# ESP32 register map
Vendor: ESPRESSIF SYSTEMS (SHANGHAI) CO., LTD.; Series: ESP32 Series; File version: 17
CPU: Xtensa LX6 r0p0, little endian, no MPU, FPU, 0 interrupt priority bits
Address unit: 32 bits
Registers are 32-bit, read-write, reset 0x0 unless marked. A register's access mark holds for its fields unless they carry their own. Offsets are from the block's base; [hi:lo] are bit positions; {n}, {i} and the like mark numbered series.

## DPORT — DPORT Peripheral
Base 0x3FF00000
0x00 PRO_BOOT_REMAP_CTRL
  [0] PRO_BOOT_REMAP
0x04 APP_BOOT_REMAP_CTRL
  [0] APP_BOOT_REMAP
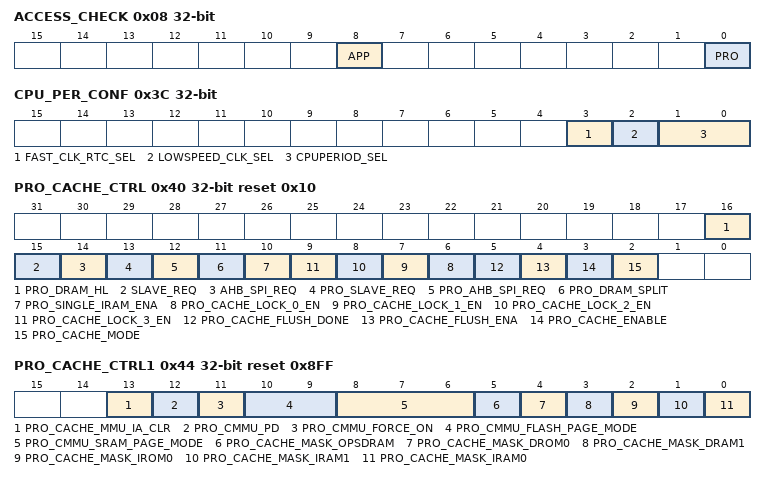
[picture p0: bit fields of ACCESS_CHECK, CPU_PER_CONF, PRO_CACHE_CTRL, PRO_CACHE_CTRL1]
0x08 ACCESS_CHECK ro
  [8] APP, [0] PRO
0x0C PRO_DPORT_APB_MASK0
  [31:0] PRODPORT_APB_MASK0
0x10 PRO_DPORT_APB_MASK1
  [31:0] PRODPORT_APB_MASK1
0x14 APP_DPORT_APB_MASK0
  [31:0] APPDPORT_APB_MASK0
0x18 APP_DPORT_APB_MASK1
  [31:0] APPDPORT_APB_MASK1
0x1C PERI_CLK_EN
0x20 PERI_RST_EN
0x24 WIFI_BB_CFG
0x28 WIFI_BB_CFG_2
0x2C APPCPU_CTRL_A reset 0x1
  [0] APPCPU_RESETTING
0x30 APPCPU_CTRL_B
  [0] APPCPU_CLKGATE_EN
0x34 APPCPU_CTRL_C
  [0] APPCPU_RUNSTALL
0x38 APPCPU_CTRL_D
  [31:0] APPCPU_BOOT_ADDR
0x3C CPU_PER_CONF
  [3] FAST_CLK_RTC_SEL, [2] LOWSPEED_CLK_SEL, [1:0] CPUPERIOD_SEL
0x40 PRO_CACHE_CTRL access per field reset 0x10
  [16] PRO_DRAM_HL rw, [15] SLAVE_REQ ro, [14] AHB_SPI_REQ ro, [13] PRO_SLAVE_REQ ro, [12] PRO_AHB_SPI_REQ ro, [11] PRO_DRAM_SPLIT rw, [10] PRO_SINGLE_IRAM_ENA rw, [n+6] PRO_CACHE_LOCK_{n}_EN rw (n=0..3), [5] PRO_CACHE_FLUSH_DONE ro, [4] PRO_CACHE_FLUSH_ENA rw, [3] PRO_CACHE_ENABLE rw, [2] PRO_CACHE_MODE rw
0x44 PRO_CACHE_CTRL1 reset 0x8FF
  [13] PRO_CACHE_MMU_IA_CLR, [12] PRO_CMMU_PD, [11] PRO_CMMU_FORCE_ON, [10:9] PRO_CMMU_FLASH_PAGE_MODE, [8:6] PRO_CMMU_SRAM_PAGE_MODE, [5] PRO_CACHE_MASK_OPSDRAM, [4] PRO_CACHE_MASK_DROM0, [3] PRO_CACHE_MASK_DRAM1, [2] PRO_CACHE_MASK_IROM0, [1] PRO_CACHE_MASK_IRAM1, [0] PRO_CACHE_MASK_IRAM0
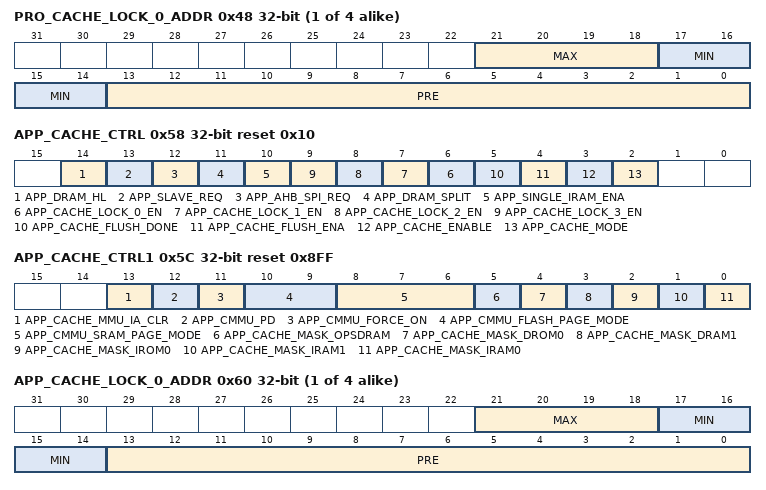
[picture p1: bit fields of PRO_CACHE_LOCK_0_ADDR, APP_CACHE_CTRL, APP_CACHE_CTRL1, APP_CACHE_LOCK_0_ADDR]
{0x48+4i} PRO_CACHE_LOCK_{i}_ADDR (i=0..3)
  [21:18] MAX, [17:14] MIN, [13:0] PRE
0x58 APP_CACHE_CTRL access per field reset 0x10
  [14] APP_DRAM_HL rw, [13] APP_SLAVE_REQ ro, [12] APP_AHB_SPI_REQ ro, [11] APP_DRAM_SPLIT rw, [10] APP_SINGLE_IRAM_ENA rw, [n+6] APP_CACHE_LOCK_{n}_EN rw (n=0..3), [5] APP_CACHE_FLUSH_DONE ro, [4] APP_CACHE_FLUSH_ENA rw, [3] APP_CACHE_ENABLE rw, [2] APP_CACHE_MODE rw
0x5C APP_CACHE_CTRL1 reset 0x8FF
  [13] APP_CACHE_MMU_IA_CLR, [12] APP_CMMU_PD, [11] APP_CMMU_FORCE_ON, [10:9] APP_CMMU_FLASH_PAGE_MODE, [8:6] APP_CMMU_SRAM_PAGE_MODE, [5] APP_CACHE_MASK_OPSDRAM, [4] APP_CACHE_MASK_DROM0, [3] APP_CACHE_MASK_DRAM1, [2] APP_CACHE_MASK_IROM0, [1] APP_CACHE_MASK_IRAM1, [0] APP_CACHE_MASK_IRAM0
{0x60+4i} APP_CACHE_LOCK_{i}_ADDR (i=0..3)
  [21:18] MAX, [17:14] MIN, [13:0] PRE
0x70 TRACEMEM_MUX_MODE
  [1:0] TRACEMEM_MUX_MODE
0x74 PRO_TRACEMEM_ENA
  [0] PRO_TRACEMEM_ENA
0x78 APP_TRACEMEM_ENA
  [0] APP_TRACEMEM_ENA
0x7C CACHE_MUX_MODE
  [1:0] CACHE_MUX_MODE
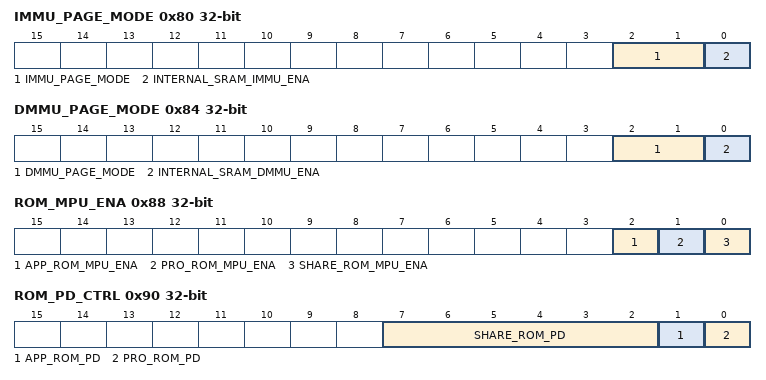
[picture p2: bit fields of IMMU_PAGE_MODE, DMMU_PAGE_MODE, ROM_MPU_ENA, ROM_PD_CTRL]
0x80 IMMU_PAGE_MODE
  [2:1] IMMU_PAGE_MODE, [0] INTERNAL_SRAM_IMMU_ENA
0x84 DMMU_PAGE_MODE
  [2:1] DMMU_PAGE_MODE, [0] INTERNAL_SRAM_DMMU_ENA
0x88 ROM_MPU_ENA
  [2] APP_ROM_MPU_ENA, [1] PRO_ROM_MPU_ENA, [0] SHARE_ROM_MPU_ENA
0x8C MEM_PD_MASK reset 0x1
  [0] LSLP_MEM_PD_MASK
0x90 ROM_PD_CTRL
  [7:2] SHARE_ROM_PD, [1] APP_ROM_PD, [0] PRO_ROM_PD
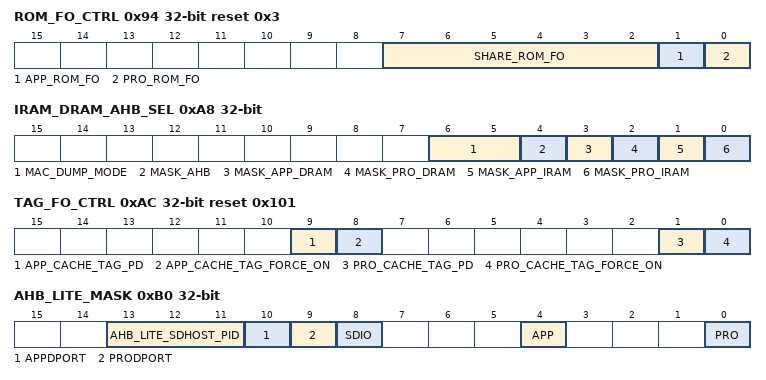
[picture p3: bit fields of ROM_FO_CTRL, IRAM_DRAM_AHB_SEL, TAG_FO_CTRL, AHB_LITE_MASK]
0x94 ROM_FO_CTRL reset 0x3
  [7:2] SHARE_ROM_FO, [1] APP_ROM_FO, [0] PRO_ROM_FO
0x98 SRAM_PD_CTRL_0
  [31:0] SRAM_PD_0
0x9C SRAM_PD_CTRL_1
  [0] SRAM_PD_1
0xA0 SRAM_FO_CTRL_0 reset 0xFFFFFFFF
  [31:0] SRAM_FO_0
0xA4 SRAM_FO_CTRL_1 reset 0x1
  [0] SRAM_FO_1
0xA8 IRAM_DRAM_AHB_SEL
  [6:5] MAC_DUMP_MODE, [4] MASK_AHB, [3] MASK_APP_DRAM, [2] MASK_PRO_DRAM, [1] MASK_APP_IRAM, [0] MASK_PRO_IRAM
0xAC TAG_FO_CTRL reset 0x101
  [9] APP_CACHE_TAG_PD, [8] APP_CACHE_TAG_FORCE_ON, [1] PRO_CACHE_TAG_PD, [0] PRO_CACHE_TAG_FORCE_ON
0xB0 AHB_LITE_MASK
  [13:11] AHB_LITE_SDHOST_PID, [10] APPDPORT, [9] PRODPORT, [8] SDIO, [4] APP, [0] PRO
0xB4 AHB_MPU_TABLE_0 reset 0xFFFFFFFF
  [31:0] AHB_ACCESS_GRANT_0
0xB8 AHB_MPU_TABLE_1 reset 0x1FF
  [8:0] AHB_ACCESS_GRANT_1
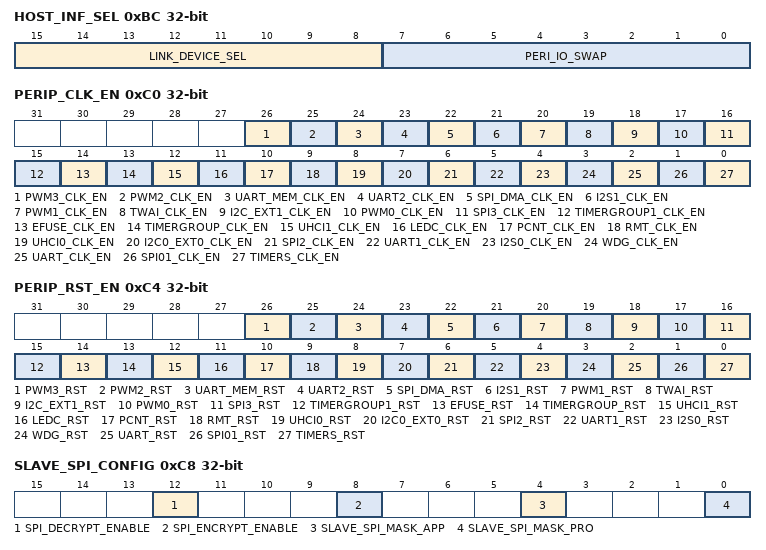
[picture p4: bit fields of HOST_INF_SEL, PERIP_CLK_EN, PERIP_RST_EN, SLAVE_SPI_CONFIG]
0xBC HOST_INF_SEL
  [15:8] LINK_DEVICE_SEL, [7:0] PERI_IO_SWAP
0xC0 PERIP_CLK_EN
  [26] PWM3_CLK_EN, [25] PWM2_CLK_EN, [24] UART_MEM_CLK_EN, [23] UART2_CLK_EN, [22] SPI_DMA_CLK_EN, [21] I2S1_CLK_EN, [20] PWM1_CLK_EN, [19] TWAI_CLK_EN, [18] I2C_EXT1_CLK_EN, [17] PWM0_CLK_EN, [16] SPI3_CLK_EN, [15] TIMERGROUP1_CLK_EN, [14] EFUSE_CLK_EN, [13] TIMERGROUP_CLK_EN, [12] UHCI1_CLK_EN, [11] LEDC_CLK_EN, [10] PCNT_CLK_EN, [9] RMT_CLK_EN, [8] UHCI0_CLK_EN, [7] I2C0_EXT0_CLK_EN, [6] SPI2_CLK_EN, [5] UART1_CLK_EN, [4] I2S0_CLK_EN, [3] WDG_CLK_EN, [2] UART_CLK_EN, [1] SPI01_CLK_EN, [0] TIMERS_CLK_EN
0xC4 PERIP_RST_EN
  [26] PWM3_RST, [25] PWM2_RST, [24] UART_MEM_RST, [23] UART2_RST, [22] SPI_DMA_RST, [21] I2S1_RST, [20] PWM1_RST, [19] TWAI_RST, [18] I2C_EXT1_RST, [17] PWM0_RST, [16] SPI3_RST, [15] TIMERGROUP1_RST, [14] EFUSE_RST, [13] TIMERGROUP_RST, [12] UHCI1_RST, [11] LEDC_RST, [10] PCNT_RST, [9] RMT_RST, [8] UHCI0_RST, [7] I2C0_EXT0_RST, [6] SPI2_RST, [5] UART1_RST, [4] I2S0_RST, [3] WDG_RST, [2] UART_RST, [1] SPI01_RST, [0] TIMERS_RST
0xC8 SLAVE_SPI_CONFIG
  [12] SPI_DECRYPT_ENABLE, [8] SPI_ENCRYPT_ENABLE, [4] SLAVE_SPI_MASK_APP, [0] SLAVE_SPI_MASK_PRO
0xCC WIFI_CLK_EN reset 0xFFFCE030
  [13:11] WIFI_CLK_BT_EN, [31:0] WIFI_CLK_EN, [2:0] WIFI_CLK_WIFI_EN, [5:0] WIFI_CLK_WIFI_BT_COMMON
0xD0 CORE_RST_EN
  [7:0] CORE_RST
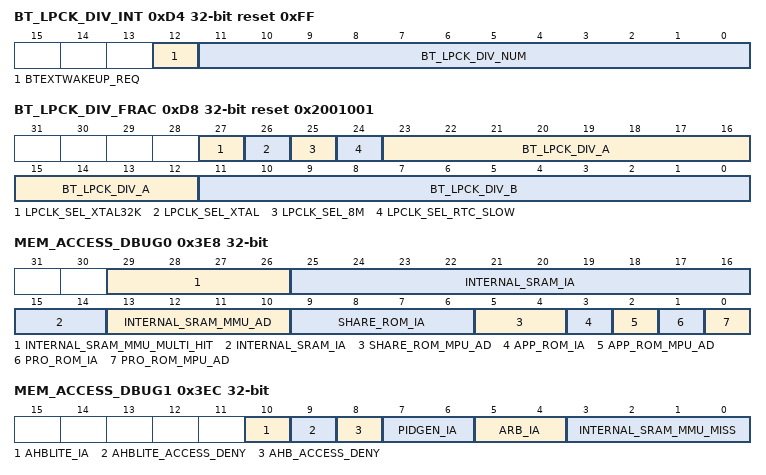
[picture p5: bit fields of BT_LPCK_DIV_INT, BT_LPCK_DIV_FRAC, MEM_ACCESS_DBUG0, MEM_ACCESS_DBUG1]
0xD4 BT_LPCK_DIV_INT reset 0xFF
  [12] BTEXTWAKEUP_REQ, [11:0] BT_LPCK_DIV_NUM
0xD8 BT_LPCK_DIV_FRAC reset 0x2001001
  [27] LPCLK_SEL_XTAL32K, [26] LPCLK_SEL_XTAL, [25] LPCLK_SEL_8M, [24] LPCLK_SEL_RTC_SLOW, [23:12] BT_LPCK_DIV_A, [11:0] BT_LPCK_DIV_B
{0xDC+4i} CPU_INTR_FROM_CPU_{i} (i=0..3)
  [0] CPU_INTR_FROM_CPU_{i}
{0xEC+4i} PRO_INTR_STATUS_{i} ro (i=0..2)
{0xF8+4i} APP_INTR_STATUS_{i} ro (i=0..2)
0x104 PRO_MAC_INTR_MAP reset 0x10
  [4:0] PRO_MAC_INTR_MAP
0x108 PRO_MAC_NMI_MAP reset 0x10
  [4:0] PRO_MAC_NMI_MAP
0x10C PRO_BB_INT_MAP reset 0x10
  [4:0] PRO_BB_INT_MAP
0x110 PRO_BT_MAC_INT_MAP reset 0x10
  [4:0] PRO_BT_MAC_INT_MAP
0x114 PRO_BT_BB_INT_MAP reset 0x10
  [4:0] PRO_BT_BB_INT_MAP
0x118 PRO_BT_BB_NMI_MAP reset 0x10
  [4:0] PRO_BT_BB_NMI_MAP
0x11C PRO_RWBT_IRQ_MAP reset 0x10
  [4:0] PRO_RWBT_IRQ_MAP
0x120 PRO_RWBLE_IRQ_MAP reset 0x10
  [4:0] PRO_RWBLE_IRQ_MAP
0x124 PRO_RWBT_NMI_MAP reset 0x10
  [4:0] PRO_RWBT_NMI_MAP
0x128 PRO_RWBLE_NMI_MAP reset 0x10
  [4:0] PRO_RWBLE_NMI_MAP
0x12C PRO_SLC0_INTR_MAP reset 0x10
  [4:0] PRO_SLC0_INTR_MAP
0x130 PRO_SLC1_INTR_MAP reset 0x10
  [4:0] PRO_SLC1_INTR_MAP
0x134 PRO_UHCI0_INTR_MAP reset 0x10
  [4:0] PRO_UHCI0_INTR_MAP
0x138 PRO_UHCI1_INTR_MAP reset 0x10
  [4:0] PRO_UHCI1_INTR_MAP
0x13C PRO_TG_T0_LEVEL_INT_MAP reset 0x10
  [4:0] PRO_TG_T0_LEVEL_INT_MAP
0x140 PRO_TG_T1_LEVEL_INT_MAP reset 0x10
  [4:0] PRO_TG_T1_LEVEL_INT_MAP
0x144 PRO_TG_WDT_LEVEL_INT_MAP reset 0x10
  [4:0] PRO_TG_WDT_LEVEL_INT_MAP
0x148 PRO_TG_LACT_LEVEL_INT_MAP reset 0x10
  [4:0] PRO_TG_LACT_LEVEL_INT_MAP
0x14C PRO_TG1_T0_LEVEL_INT_MAP reset 0x10
  [4:0] PRO_TG1_T0_LEVEL_INT_MAP
0x150 PRO_TG1_T1_LEVEL_INT_MAP reset 0x10
  [4:0] PRO_TG1_T1_LEVEL_INT_MAP
0x154 PRO_TG1_WDT_LEVEL_INT_MAP reset 0x10
  [4:0] PRO_TG1_WDT_LEVEL_INT_MAP
0x158 PRO_TG1_LACT_LEVEL_INT_MAP reset 0x10
  [4:0] PRO_TG1_LACT_LEVEL_INT_MAP
0x15C PRO_GPIO_INTERRUPT_MAP reset 0x10
  [4:0] PRO_GPIO_INTERRUPT_PRO_MAP
0x160 PRO_GPIO_INTERRUPT_NMI_MAP reset 0x10
  [4:0] PRO_GPIO_INTERRUPT_PRO_NMI_MAP
{0x164+4i} PRO_CPU_INTR_FROM_CPU_{i}_MAP reset 0x10 (i=0..3)
  [4:0] PRO_CPU_INTR_FROM_CPU_{i}_MAP
{0x174+4i} PRO_SPI_INTR_{i}_MAP reset 0x10 (i=0..3)
  [4:0] PRO_SPI_INTR_{i}_MAP
0x184 PRO_I2S0_INT_MAP reset 0x10
  [4:0] PRO_I2S0_INT_MAP
0x188 PRO_I2S1_INT_MAP reset 0x10
  [4:0] PRO_I2S1_INT_MAP
0x18C PRO_UART_INTR_MAP reset 0x10
  [4:0] PRO_UART_INTR_MAP
0x190 PRO_UART1_INTR_MAP reset 0x10
  [4:0] PRO_UART1_INTR_MAP
0x194 PRO_UART2_INTR_MAP reset 0x10
  [4:0] PRO_UART2_INTR_MAP
0x198 PRO_SDIO_HOST_INTERRUPT_MAP reset 0x10
  [4:0] PRO_SDIO_HOST_INTERRUPT_MAP
0x19C PRO_EMAC_INT_MAP reset 0x10
  [4:0] PRO_EMAC_INT_MAP
{0x1A0+4i} PRO_PWM{i}_INTR_MAP reset 0x10 (i=0..3)
  [4:0] PRO_PWM{i}_INTR_MAP
0x1B0 PRO_LEDC_INT_MAP reset 0x10
  [4:0] PRO_LEDC_INT_MAP
0x1B4 PRO_EFUSE_INT_MAP reset 0x10
  [4:0] PRO_EFUSE_INT_MAP
0x1B8 PRO_CAN_INT_MAP reset 0x10
  [4:0] PRO_CAN_INT_MAP
0x1BC PRO_RTC_CORE_INTR_MAP reset 0x10
  [4:0] PRO_RTC_CORE_INTR_MAP
0x1C0 PRO_RMT_INTR_MAP reset 0x10
  [4:0] PRO_RMT_INTR_MAP
0x1C4 PRO_PCNT_INTR_MAP reset 0x10
  [4:0] PRO_PCNT_INTR_MAP
0x1C8 PRO_I2C_EXT0_INTR_MAP reset 0x10
  [4:0] PRO_I2C_EXT0_INTR_MAP
0x1CC PRO_I2C_EXT1_INTR_MAP reset 0x10
  [4:0] PRO_I2C_EXT1_INTR_MAP
0x1D0 PRO_RSA_INTR_MAP reset 0x10
  [4:0] PRO_RSA_INTR_MAP
{0x1D0+4i} PRO_SPI{i}_DMA_INT_MAP reset 0x10 (i=1..3)
  [4:0] PRO_SPI{i}_DMA_INT_MAP
0x1E0 PRO_WDG_INT_MAP reset 0x10
  [4:0] PRO_WDG_INT_MAP
0x1E4 PRO_TIMER_INT1_MAP reset 0x10
  [4:0] PRO_TIMER_INT1_MAP
0x1E8 PRO_TIMER_INT2_MAP reset 0x10
  [4:0] PRO_TIMER_INT2_MAP
0x1EC PRO_TG_T0_EDGE_INT_MAP reset 0x10
  [4:0] PRO_TG_T0_EDGE_INT_MAP
0x1F0 PRO_TG_T1_EDGE_INT_MAP reset 0x10
  [4:0] PRO_TG_T1_EDGE_INT_MAP
0x1F4 PRO_TG_WDT_EDGE_INT_MAP reset 0x10
  [4:0] PRO_TG_WDT_EDGE_INT_MAP
0x1F8 PRO_TG_LACT_EDGE_INT_MAP reset 0x10
  [4:0] PRO_TG_LACT_EDGE_INT_MAP
0x1FC PRO_TG1_T0_EDGE_INT_MAP reset 0x10
  [4:0] PRO_TG1_T0_EDGE_INT_MAP
0x200 PRO_TG1_T1_EDGE_INT_MAP reset 0x10
  [4:0] PRO_TG1_T1_EDGE_INT_MAP
0x204 PRO_TG1_WDT_EDGE_INT_MAP reset 0x10
  [4:0] PRO_TG1_WDT_EDGE_INT_MAP
0x208 PRO_TG1_LACT_EDGE_INT_MAP reset 0x10
  [4:0] PRO_TG1_LACT_EDGE_INT_MAP
0x20C PRO_MMU_IA_INT_MAP reset 0x10
  [4:0] PRO_MMU_IA_INT_MAP
0x210 PRO_MPU_IA_INT_MAP reset 0x10
  [4:0] PRO_MPU_IA_INT_MAP
0x214 PRO_CACHE_IA_INT_MAP reset 0x10
  [4:0] PRO_CACHE_IA_INT_MAP
0x218 APP_MAC_INTR_MAP reset 0x10
  [4:0] APP_MAC_INTR_MAP
0x21C APP_MAC_NMI_MAP reset 0x10
  [4:0] APP_MAC_NMI_MAP
0x220 APP_BB_INT_MAP reset 0x10
  [4:0] APP_BB_INT_MAP
0x224 APP_BT_MAC_INT_MAP reset 0x10
  [4:0] APP_BT_MAC_INT_MAP
0x228 APP_BT_BB_INT_MAP reset 0x10
  [4:0] APP_BT_BB_INT_MAP
0x22C APP_BT_BB_NMI_MAP reset 0x10
  [4:0] APP_BT_BB_NMI_MAP
0x230 APP_RWBT_IRQ_MAP reset 0x10
  [4:0] APP_RWBT_IRQ_MAP
0x234 APP_RWBLE_IRQ_MAP reset 0x10
  [4:0] APP_RWBLE_IRQ_MAP
0x238 APP_RWBT_NMI_MAP reset 0x10
  [4:0] APP_RWBT_NMI_MAP
0x23C APP_RWBLE_NMI_MAP reset 0x10
  [4:0] APP_RWBLE_NMI_MAP
0x240 APP_SLC0_INTR_MAP reset 0x10
  [4:0] APP_SLC0_INTR_MAP
0x244 APP_SLC1_INTR_MAP reset 0x10
  [4:0] APP_SLC1_INTR_MAP
0x248 APP_UHCI0_INTR_MAP reset 0x10
  [4:0] APP_UHCI0_INTR_MAP
0x24C APP_UHCI1_INTR_MAP reset 0x10
  [4:0] APP_UHCI1_INTR_MAP
0x250 APP_TG_T0_LEVEL_INT_MAP reset 0x10
  [4:0] APP_TG_T0_LEVEL_INT_MAP
0x254 APP_TG_T1_LEVEL_INT_MAP reset 0x10
  [4:0] APP_TG_T1_LEVEL_INT_MAP
0x258 APP_TG_WDT_LEVEL_INT_MAP reset 0x10
  [4:0] APP_TG_WDT_LEVEL_INT_MAP
0x25C APP_TG_LACT_LEVEL_INT_MAP reset 0x10
  [4:0] APP_TG_LACT_LEVEL_INT_MAP
0x260 APP_TG1_T0_LEVEL_INT_MAP reset 0x10
  [4:0] APP_TG1_T0_LEVEL_INT_MAP
0x264 APP_TG1_T1_LEVEL_INT_MAP reset 0x10
  [4:0] APP_TG1_T1_LEVEL_INT_MAP
0x268 APP_TG1_WDT_LEVEL_INT_MAP reset 0x10
  [4:0] APP_TG1_WDT_LEVEL_INT_MAP
0x26C APP_TG1_LACT_LEVEL_INT_MAP reset 0x10
  [4:0] APP_TG1_LACT_LEVEL_INT_MAP
0x270 APP_GPIO_INTERRUPT_MAP reset 0x10
  [4:0] APP_GPIO_INTERRUPT_APP_MAP
0x274 APP_GPIO_INTERRUPT_NMI_MAP reset 0x10
  [4:0] APP_GPIO_INTERRUPT_APP_NMI_MAP
{0x278+4i} APP_CPU_INTR_FROM_CPU_{i}_MAP reset 0x10 (i=0..3)
  [4:0] APP_CPU_INTR_FROM_CPU_{i}_MAP
{0x288+4i} APP_SPI_INTR_{i}_MAP reset 0x10 (i=0..3)
  [4:0] APP_SPI_INTR_{i}_MAP
0x298 APP_I2S0_INT_MAP reset 0x10
  [4:0] APP_I2S0_INT_MAP
0x29C APP_I2S1_INT_MAP reset 0x10
  [4:0] APP_I2S1_INT_MAP
0x2A0 APP_UART_INTR_MAP reset 0x10
  [4:0] APP_UART_INTR_MAP
0x2A4 APP_UART1_INTR_MAP reset 0x10
  [4:0] APP_UART1_INTR_MAP
0x2A8 APP_UART2_INTR_MAP reset 0x10
  [4:0] APP_UART2_INTR_MAP
0x2AC APP_SDIO_HOST_INTERRUPT_MAP reset 0x10
  [4:0] APP_SDIO_HOST_INTERRUPT_MAP
0x2B0 APP_EMAC_INT_MAP reset 0x10
  [4:0] APP_EMAC_INT_MAP
{0x2B4+4i} APP_PWM{i}_INTR_MAP reset 0x10 (i=0..3)
  [4:0] APP_PWM{i}_INTR_MAP
0x2C4 APP_LEDC_INT_MAP reset 0x10
  [4:0] APP_LEDC_INT_MAP
0x2C8 APP_EFUSE_INT_MAP reset 0x10
  [4:0] APP_EFUSE_INT_MAP
0x2CC APP_CAN_INT_MAP reset 0x10
  [4:0] APP_CAN_INT_MAP
0x2D0 APP_RTC_CORE_INTR_MAP reset 0x10
  [4:0] APP_RTC_CORE_INTR_MAP
0x2D4 APP_RMT_INTR_MAP reset 0x10
  [4:0] APP_RMT_INTR_MAP
0x2D8 APP_PCNT_INTR_MAP reset 0x10
  [4:0] APP_PCNT_INTR_MAP
0x2DC APP_I2C_EXT0_INTR_MAP reset 0x10
  [4:0] APP_I2C_EXT0_INTR_MAP
0x2E0 APP_I2C_EXT1_INTR_MAP reset 0x10
  [4:0] APP_I2C_EXT1_INTR_MAP
0x2E4 APP_RSA_INTR_MAP reset 0x10
  [4:0] APP_RSA_INTR_MAP
{0x2E4+4i} APP_SPI{i}_DMA_INT_MAP reset 0x10 (i=1..3)
  [4:0] APP_SPI{i}_DMA_INT_MAP
0x2F4 APP_WDG_INT_MAP reset 0x10
  [4:0] APP_WDG_INT_MAP
0x2F8 APP_TIMER_INT1_MAP reset 0x10
  [4:0] APP_TIMER_INT1_MAP
0x2FC APP_TIMER_INT2_MAP reset 0x10
  [4:0] APP_TIMER_INT2_MAP
0x300 APP_TG_T0_EDGE_INT_MAP reset 0x10
  [4:0] APP_TG_T0_EDGE_INT_MAP
0x304 APP_TG_T1_EDGE_INT_MAP reset 0x10
  [4:0] APP_TG_T1_EDGE_INT_MAP
0x308 APP_TG_WDT_EDGE_INT_MAP reset 0x10
  [4:0] APP_TG_WDT_EDGE_INT_MAP
0x30C APP_TG_LACT_EDGE_INT_MAP reset 0x10
  [4:0] APP_TG_LACT_EDGE_INT_MAP
0x310 APP_TG1_T0_EDGE_INT_MAP reset 0x10
  [4:0] APP_TG1_T0_EDGE_INT_MAP
0x314 APP_TG1_T1_EDGE_INT_MAP reset 0x10
  [4:0] APP_TG1_T1_EDGE_INT_MAP
0x318 APP_TG1_WDT_EDGE_INT_MAP reset 0x10
  [4:0] APP_TG1_WDT_EDGE_INT_MAP
0x31C APP_TG1_LACT_EDGE_INT_MAP reset 0x10
  [4:0] APP_TG1_LACT_EDGE_INT_MAP
0x320 APP_MMU_IA_INT_MAP reset 0x10
  [4:0] APP_MMU_IA_INT_MAP
0x324 APP_MPU_IA_INT_MAP reset 0x10
  [4:0] APP_MPU_IA_INT_MAP
0x328 APP_CACHE_IA_INT_MAP reset 0x10
  [4:0] APP_CACHE_IA_INT_MAP
0x32C AHBLITE_MPU_TABLE_UART
  [5:0] UART_ACCESS_GRANT_CONFIG
0x330 AHBLITE_MPU_TABLE_SPI1
  [5:0] SPI1_ACCESS_GRANT_CONFIG
0x334 AHBLITE_MPU_TABLE_SPI0
  [5:0] SPI0_ACCESS_GRANT_CONFIG
0x338 AHBLITE_MPU_TABLE_GPIO
  [5:0] GPIO_ACCESS_GRANT_CONFIG
0x33C AHBLITE_MPU_TABLE_FE2
  [5:0] FE2_ACCESS_GRANT_CONFIG
0x340 AHBLITE_MPU_TABLE_FE
  [5:0] FE_ACCESS_GRANT_CONFIG
0x344 AHBLITE_MPU_TABLE_TIMER
  [5:0] TIMER_ACCESS_GRANT_CONFIG
0x348 AHBLITE_MPU_TABLE_RTC
  [5:0] RTC_ACCESS_GRANT_CONFIG
0x34C AHBLITE_MPU_TABLE_IO_MUX
  [5:0] IOMUX_ACCESS_GRANT_CONFIG
0x350 AHBLITE_MPU_TABLE_WDG
  [5:0] WDG_ACCESS_GRANT_CONFIG
0x354 AHBLITE_MPU_TABLE_HINF
  [5:0] HINF_ACCESS_GRANT_CONFIG
0x358 AHBLITE_MPU_TABLE_UHCI1
  [5:0] UHCI1_ACCESS_GRANT_CONFIG
0x35C AHBLITE_MPU_TABLE_MISC
  [5:0] MISC_ACCESS_GRANT_CONFIG
0x360 AHBLITE_MPU_TABLE_I2C
  [5:0] I2C_ACCESS_GRANT_CONFIG
0x364 AHBLITE_MPU_TABLE_I2S0
  [5:0] I2S0_ACCESS_GRANT_CONFIG
0x368 AHBLITE_MPU_TABLE_UART1
  [5:0] UART1_ACCESS_GRANT_CONFIG
0x36C AHBLITE_MPU_TABLE_BT
  [5:0] BT_ACCESS_GRANT_CONFIG
0x370 AHBLITE_MPU_TABLE_BT_BUFFER
  [5:0] BTBUFFER_ACCESS_GRANT_CONFIG
0x374 AHBLITE_MPU_TABLE_I2C_EXT0
  [5:0] I2CEXT0_ACCESS_GRANT_CONFIG
0x378 AHBLITE_MPU_TABLE_UHCI0
  [5:0] UHCI0_ACCESS_GRANT_CONFIG
0x37C AHBLITE_MPU_TABLE_SLCHOST
  [5:0] SLCHOST_ACCESS_GRANT_CONFIG
0x380 AHBLITE_MPU_TABLE_RMT
  [5:0] RMT_ACCESS_GRANT_CONFIG
0x384 AHBLITE_MPU_TABLE_PCNT
  [5:0] PCNT_ACCESS_GRANT_CONFIG
0x388 AHBLITE_MPU_TABLE_SLC
  [5:0] SLC_ACCESS_GRANT_CONFIG
0x38C AHBLITE_MPU_TABLE_LEDC
  [5:0] LEDC_ACCESS_GRANT_CONFIG
0x390 AHBLITE_MPU_TABLE_EFUSE
  [5:0] EFUSE_ACCESS_GRANT_CONFIG
0x394 AHBLITE_MPU_TABLE_SPI_ENCRYPT
  [5:0] SPI_ENCRYPY_ACCESS_GRANT_CONFIG
0x398 AHBLITE_MPU_TABLE_BB
  [5:0] BB_ACCESS_GRANT_CONFIG
0x39C AHBLITE_MPU_TABLE_PWM0
  [5:0] PWM0_ACCESS_GRANT_CONFIG
0x3A0 AHBLITE_MPU_TABLE_TIMERGROUP
  [5:0] TIMERGROUP_ACCESS_GRANT_CONFIG
0x3A4 AHBLITE_MPU_TABLE_TIMERGROUP1
  [5:0] TIMERGROUP1_ACCESS_GRANT_CONFIG
0x3A8 AHBLITE_MPU_TABLE_SPI2
  [5:0] SPI2_ACCESS_GRANT_CONFIG
0x3AC AHBLITE_MPU_TABLE_SPI3
  [5:0] SPI3_ACCESS_GRANT_CONFIG
0x3B0 AHBLITE_MPU_TABLE_APB_CTRL
  [5:0] APBCTRL_ACCESS_GRANT_CONFIG
0x3B4 AHBLITE_MPU_TABLE_I2C_EXT1
  [5:0] I2CEXT1_ACCESS_GRANT_CONFIG
0x3B8 AHBLITE_MPU_TABLE_SDIO_HOST
  [5:0] SDIOHOST_ACCESS_GRANT_CONFIG
0x3BC AHBLITE_MPU_TABLE_EMAC
  [5:0] EMAC_ACCESS_GRANT_CONFIG
0x3C0 AHBLITE_MPU_TABLE_CAN
  [5:0] CAN_ACCESS_GRANT_CONFIG
0x3C4 AHBLITE_MPU_TABLE_PWM1
  [5:0] PWM1_ACCESS_GRANT_CONFIG
0x3C8 AHBLITE_MPU_TABLE_I2S1
  [5:0] I2S1_ACCESS_GRANT_CONFIG
0x3CC AHBLITE_MPU_TABLE_UART2
  [5:0] UART2_ACCESS_GRANT_CONFIG
0x3D0 AHBLITE_MPU_TABLE_PWM2
  [5:0] PWM2_ACCESS_GRANT_CONFIG
0x3D4 AHBLITE_MPU_TABLE_PWM3
  [5:0] PWM3_ACCESS_GRANT_CONFIG
0x3D8 AHBLITE_MPU_TABLE_RWBT
  [5:0] RWBT_ACCESS_GRANT_CONFIG
0x3DC AHBLITE_MPU_TABLE_BTMAC
  [5:0] BTMAC_ACCESS_GRANT_CONFIG
0x3E0 AHBLITE_MPU_TABLE_WIFIMAC
  [5:0] WIFIMAC_ACCESS_GRANT_CONFIG
0x3E4 AHBLITE_MPU_TABLE_PWR
  [5:0] PWR_ACCESS_GRANT_CONFIG
0x3E8 MEM_ACCESS_DBUG0 ro
  [29:26] INTERNAL_SRAM_MMU_MULTI_HIT, [25:14] INTERNAL_SRAM_IA, [13:10] INTERNAL_SRAM_MMU_AD, [9:6] SHARE_ROM_IA, [5:4] SHARE_ROM_MPU_AD, [3] APP_ROM_IA, [2] APP_ROM_MPU_AD, [1] PRO_ROM_IA, [0] PRO_ROM_MPU_AD
0x3EC MEM_ACCESS_DBUG1 ro
  [10] AHBLITE_IA, [9] AHBLITE_ACCESS_DENY, [8] AHB_ACCESS_DENY, [7:6] PIDGEN_IA, [5:4] ARB_IA, [3:0] INTERNAL_SRAM_MMU_MISS
0x3F0 PRO_DCACHE_DBUG0 access per field
  [23] PRO_RX_END ro, [22] PRO_SLAVE_WDATA_V ro, [21] PRO_SLAVE_WR ro, [20] PRO_TX_END ro, [19] PRO_WR_BAK_TO_READ ro, [18:7] PRO_CACHE_STATE ro, [6:1] PRO_CACHE_IA ro, [0] PRO_SLAVE_WDATA rw, [0] PRO_CACHE_MMU_IA ro
0x3F4 PRO_DCACHE_DBUG1 ro
  [31:0] PRO_CTAG_RAM_RDATA
0x3F8 PRO_DCACHE_DBUG2 ro
  [26:0] PRO_CACHE_VADDR
0x3FC PRO_DCACHE_DBUG3 access per field
  [15] PRO_CACHE_IRAM0_PID_ERROR ro, [14] PRO_CPU_DISABLED_CACHE_IA_DROM0 rw, [13] PRO_CPU_DISABLED_CACHE_IA_IRAM0 rw, [12] PRO_CPU_DISABLED_CACHE_IA_IRAM1 rw, [11] PRO_CPU_DISABLED_CACHE_IA_IROM0 rw, [10] PRO_CPU_DISABLED_CACHE_IA_DRAM1 rw, [14:9] PRO_CPU_DISABLED_CACHE_IA ro, [9] PRO_CPU_DISABLED_CACHE_IA_OPPOSITE rw, [8:0] PRO_MMU_RDATA ro
0x400 PRO_DCACHE_DBUG4 ro
  [19:0] PRO_DRAM1ADDR0_IA
0x404 PRO_DCACHE_DBUG5 ro
  [19:0] PRO_DROM0ADDR0_IA
0x408 PRO_DCACHE_DBUG6 ro
  [19:0] PRO_IRAM0ADDR_IA
0x40C PRO_DCACHE_DBUG7 ro
  [19:0] PRO_IRAM1ADDR_IA
0x410 PRO_DCACHE_DBUG8 ro
  [19:0] PRO_IROM0ADDR_IA
0x414 PRO_DCACHE_DBUG9 ro
  [19:0] PRO_OPSDRAMADDR_IA
0x418 APP_DCACHE_DBUG0 access per field
  [23] APP_RX_END ro, [22] APP_SLAVE_WDATA_V ro, [21] APP_SLAVE_WR ro, [20] APP_TX_END ro, [19] APP_WR_BAK_TO_READ ro, [18:7] APP_CACHE_STATE ro, [6:1] APP_CACHE_IA ro, [0] APP_SLAVE_WDATA rw, [0] APP_CACHE_MMU_IA ro
0x41C APP_DCACHE_DBUG1 ro
  [31:0] APP_CTAG_RAM_RDATA
0x420 APP_DCACHE_DBUG2 ro
  [26:0] APP_CACHE_VADDR
0x424 APP_DCACHE_DBUG3 access per field
  [15] APP_CACHE_IRAM0_PID_ERROR ro, [14] APP_CPU_DISABLED_CACHE_IA_DROM0 rw, [13] APP_CPU_DISABLED_CACHE_IA_IRAM0 rw, [12] APP_CPU_DISABLED_CACHE_IA_IRAM1 rw, [11] APP_CPU_DISABLED_CACHE_IA_IROM0 rw, [10] APP_CPU_DISABLED_CACHE_IA_DRAM1 rw, [14:9] APP_CPU_DISABLED_CACHE_IA ro, [9] APP_CPU_DISABLED_CACHE_IA_OPPOSITE rw, [8:0] APP_MMU_RDATA ro
0x428 APP_DCACHE_DBUG4 ro
  [19:0] APP_DRAM1ADDR0_IA
0x42C APP_DCACHE_DBUG5 ro
  [19:0] APP_DROM0ADDR0_IA
0x430 APP_DCACHE_DBUG6 ro
  [19:0] APP_IRAM0ADDR_IA
0x434 APP_DCACHE_DBUG7 ro
  [19:0] APP_IRAM1ADDR_IA
0x438 APP_DCACHE_DBUG8 ro
  [19:0] APP_IROM0ADDR_IA
0x43C APP_DCACHE_DBUG9 ro
  [19:0] APP_OPSDRAMADDR_IA
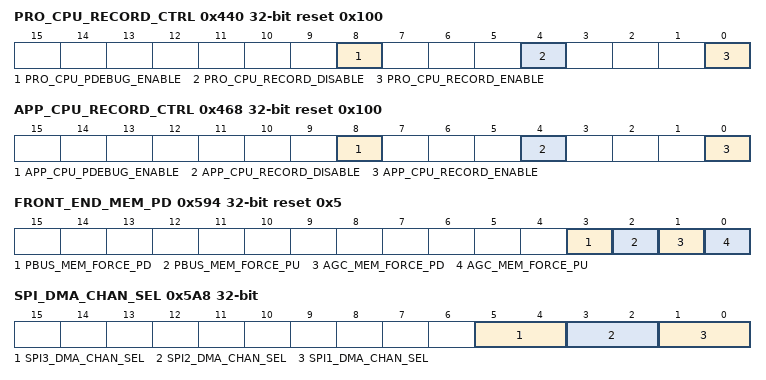
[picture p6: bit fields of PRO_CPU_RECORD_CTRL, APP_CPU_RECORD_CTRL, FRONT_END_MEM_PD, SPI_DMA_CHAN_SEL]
0x440 PRO_CPU_RECORD_CTRL reset 0x100
  [8] PRO_CPU_PDEBUG_ENABLE, [4] PRO_CPU_RECORD_DISABLE, [0] PRO_CPU_RECORD_ENABLE
0x444 PRO_CPU_RECORD_STATUS ro
  [0] PRO_CPU_RECORDING
0x448 PRO_CPU_RECORD_PID ro
  [2:0] RECORD_PRO_PID
0x44C PRO_CPU_RECORD_PDEBUGINST access per field
  [27:24] RECORD_PDEBUGINST_CINTL rw, [21] RECORD_PDEBUGINST_LOOP rw, [20] RECORD_PDEBUGINST_LOOP_REP rw, [14:12] RECORD_PDEBUGINST_ISRC rw, [31:0] RECORD_PRO_PDEBUGINST ro, [7:0] RECORD_PDEBUGINST_SZ rw
0x450 PRO_CPU_RECORD_PDEBUGSTATUS access per field
  [7:0] RECORD_PRO_PDEBUGSTATUS ro, [5:0] RECORD_PDEBUGSTATUS_BBCAUSE rw, [5:0] RECORD_PDEBUGSTATUS_INSNTYPE rw
0x454 PRO_CPU_RECORD_PDEBUGDATA access per field
  [19] RECORD_PDEBUGDATA_STALL_ITERDIV rw, [18] RECORD_PDEBUGDATA_STALL_ITERMUL rw, [17] RECORD_PDEBUGDATA_DEP_HALT rw, [16] RECORD_PDEBUGDATA_DEP_MEMW rw, [21:16] RECORD_PDEBUGDATA_EXCCAUSE rw, [16] RECORD_PDEBUGDATA_STALL_BANKCONFL rw, [15] RECORD_PDEBUGDATA_STALL_BPLOAD rw, [14] RECORD_PDEBUGDATA_STALL_LSPROC rw, [13] RECORD_PDEBUGDATA_STALL_L32R rw, [12] RECORD_PDEBUGDATA_DEP rw, [12] RECORD_PDEBUGDATA_STALL_BPIFETCH rw, [11] RECORD_PDEBUGDATA_DEP_STR rw, [10] RECORD_PDEBUGDATA_STALL_RUN rw, [10] RECORD_PDEBUGDATA_INSNTYPE_XSR rw, [9] RECORD_PDEBUGDATA_STALL_TIE rw, [9] RECORD_PDEBUGDATA_INSNTYPE_WSR rw, [8] RECORD_PDEBUGDATA_DEP_LSU rw, [8] RECORD_PDEBUGDATA_STALL_IPIF rw, [8] RECORD_PDEBUGDATA_INSNTYPE_RSR rw, [7] RECORD_PDEBUGDATA_STALL_IRAMBUSY rw, [6] RECORD_PDEBUGDATA_STALL_ICM rw, [4] RECORD_PDEBUGDATA_STALL_LSU rw, [3] RECORD_PDEBUGDATA_STALL_DCM rw, [2] RECORD_PDEBUGDATA_STALL_BUFFCONFL rw, [13:2] RECORD_PDEBUGDATA_INSNTYPE_ER rw, [1] RECORD_PDEBUGDATA_STALL_BUFF rw, [1] RECORD_PDEBUGDATA_INSNTYPE_WER rw, [31:0] RECORD_PRO_PDEBUGDATA ro, [0] RECORD_PDEBUGDATA_DEP_OTHER rw, [4:0] RECORD_PDEBUGDATA_EXCVEC rw, [7:0] RECORD_PDEBUGDATA_INSNTYPE_SR rw, [0] RECORD_PDEBUGDATA_INSNTYPE_RER rw
0x458 PRO_CPU_RECORD_PDEBUGPC ro
  [31:0] RECORD_PRO_PDEBUGPC
0x45C PRO_CPU_RECORD_PDEBUGLS0STAT access per field
  [23:20] RECORD_PDEBUGLS0STAT_TGT rw, [18:17] RECORD_PDEBUGLS0STAT_STCOH rw, [16] RECORD_PDEBUGLS0STAT_COH rw, [13] RECORD_PDEBUGLS0STAT_WB rw, [12] RECORD_PDEBUGLS0STAT_UC rw, [10] RECORD_PDEBUGLS0STAT_DCH rw, [9] RECORD_PDEBUGLS0STAT_DCM rw, [8] RECORD_PDEBUGLS0STAT_DTLBM rw, [7:4] RECORD_PDEBUGLS0STAT_SZ rw, [31:0] RECORD_PRO_PDEBUGLS0STAT ro, [3:0] RECORD_PDEBUGLS0STAT_TYPE rw
0x460 PRO_CPU_RECORD_PDEBUGLS0ADDR ro
  [31:0] RECORD_PRO_PDEBUGLS0ADDR
0x464 PRO_CPU_RECORD_PDEBUGLS0DATA ro
  [31:0] RECORD_PRO_PDEBUGLS0DATA
0x468 APP_CPU_RECORD_CTRL reset 0x100
  [8] APP_CPU_PDEBUG_ENABLE, [4] APP_CPU_RECORD_DISABLE, [0] APP_CPU_RECORD_ENABLE
0x46C APP_CPU_RECORD_STATUS ro
  [0] APP_CPU_RECORDING
0x470 APP_CPU_RECORD_PID ro
  [2:0] RECORD_APP_PID
0x474 APP_CPU_RECORD_PDEBUGINST ro
  [31:0] RECORD_APP_PDEBUGINST
0x478 APP_CPU_RECORD_PDEBUGSTATUS ro
  [7:0] RECORD_APP_PDEBUGSTATUS
0x47C APP_CPU_RECORD_PDEBUGDATA ro
  [31:0] RECORD_APP_PDEBUGDATA
0x480 APP_CPU_RECORD_PDEBUGPC ro
  [31:0] RECORD_APP_PDEBUGPC
0x484 APP_CPU_RECORD_PDEBUGLS0STAT ro
  [31:0] RECORD_APP_PDEBUGLS0STAT
0x488 APP_CPU_RECORD_PDEBUGLS0ADDR ro
  [31:0] RECORD_APP_PDEBUGLS0ADDR
0x48C APP_CPU_RECORD_PDEBUGLS0DATA ro
  [31:0] RECORD_APP_PDEBUGLS0DATA
0x490 RSA_PD_CTRL
  [0] RSA_PD
{0x494+4i} ROM_MPU_TABLE{i} reset 0x1 (i=0..3)
  [1:0] ROM_MPU_TABLE{i}
{0x4A4+4i} SHROM_MPU_TABLE{i} reset 0x1 (i=0..23)
  [1:0] SHROM_MPU_TABLE{i}
0x504 IMMU_TABLE0
  [6:0] IMMU_TABLE0
0x508 IMMU_TABLE1 reset 0x1
  [6:0] IMMU_TABLE1
0x50C IMMU_TABLE2 reset 0x2
  [6:0] IMMU_TABLE2
0x510 IMMU_TABLE3 reset 0x3
  [6:0] IMMU_TABLE3
0x514 IMMU_TABLE4 reset 0x4
  [6:0] IMMU_TABLE4
0x518 IMMU_TABLE5 reset 0x5
  [6:0] IMMU_TABLE5
0x51C IMMU_TABLE6 reset 0x6
  [6:0] IMMU_TABLE6
0x520 IMMU_TABLE7 reset 0x7
  [6:0] IMMU_TABLE7
0x524 IMMU_TABLE8 reset 0x8
  [6:0] IMMU_TABLE8
0x528 IMMU_TABLE9 reset 0x9
  [6:0] IMMU_TABLE9
0x52C IMMU_TABLE10 reset 0xA
  [6:0] IMMU_TABLE10
0x530 IMMU_TABLE11 reset 0xB
  [6:0] IMMU_TABLE11
0x534 IMMU_TABLE12 reset 0xC
  [6:0] IMMU_TABLE12
0x538 IMMU_TABLE13 reset 0xD
  [6:0] IMMU_TABLE13
0x53C IMMU_TABLE14 reset 0xE
  [6:0] IMMU_TABLE14
0x540 IMMU_TABLE15 reset 0xF
  [6:0] IMMU_TABLE15
0x544 DMMU_TABLE0
  [6:0] DMMU_TABLE0
0x548 DMMU_TABLE1 reset 0x1
  [6:0] DMMU_TABLE1
0x54C DMMU_TABLE2 reset 0x2
  [6:0] DMMU_TABLE2
0x550 DMMU_TABLE3 reset 0x3
  [6:0] DMMU_TABLE3
0x554 DMMU_TABLE4 reset 0x4
  [6:0] DMMU_TABLE4
0x558 DMMU_TABLE5 reset 0x5
  [6:0] DMMU_TABLE5
0x55C DMMU_TABLE6 reset 0x6
  [6:0] DMMU_TABLE6
0x560 DMMU_TABLE7 reset 0x7
  [6:0] DMMU_TABLE7
0x564 DMMU_TABLE8 reset 0x8
  [6:0] DMMU_TABLE8
0x568 DMMU_TABLE9 reset 0x9
  [6:0] DMMU_TABLE9
0x56C DMMU_TABLE10 reset 0xA
  [6:0] DMMU_TABLE10
0x570 DMMU_TABLE11 reset 0xB
  [6:0] DMMU_TABLE11
0x574 DMMU_TABLE12 reset 0xC
  [6:0] DMMU_TABLE12
0x578 DMMU_TABLE13 reset 0xD
  [6:0] DMMU_TABLE13
0x57C DMMU_TABLE14 reset 0xE
  [6:0] DMMU_TABLE14
0x580 DMMU_TABLE15 reset 0xF
  [6:0] DMMU_TABLE15
0x584 PRO_INTRUSION_CTRL reset 0x1
  [0] PRO_INTRUSION_RECORD_RESET_N
0x588 PRO_INTRUSION_STATUS ro
  [3:0] PRO_INTRUSION_RECORD
0x58C APP_INTRUSION_CTRL reset 0x1
  [0] APP_INTRUSION_RECORD_RESET_N
0x590 APP_INTRUSION_STATUS ro
  [3:0] APP_INTRUSION_RECORD
0x594 FRONT_END_MEM_PD reset 0x5
  [3] PBUS_MEM_FORCE_PD, [2] PBUS_MEM_FORCE_PU, [1] AGC_MEM_FORCE_PD, [0] AGC_MEM_FORCE_PU
0x598 MMU_IA_INT_EN
  [23:0] MMU_IA_INT_EN
0x59C MPU_IA_INT_EN
  [16:0] MPU_IA_INT_EN
0x5A0 CACHE_IA_INT_EN
  [19] CACHE_IA_INT_PRO_OPPOSITE — PRO CPU invalid access to APP CPU cache when cache disabled
  [18] CACHE_IA_INT_PRO_DRAM1 — PRO CPU invalid access to DRAM1 when cache is disabled
  [17] CACHE_IA_INT_PRO_IROM0 — PRO CPU invalid access to IROM0 when cache is disabled
  [16] CACHE_IA_INT_PRO_IRAM1 — PRO CPU invalid access to IRAM1 when cache is disabled
  [15] CACHE_IA_INT_PRO_IRAM0 — PRO CPU invalid access to IRAM0 when cache is disabled
  [14] CACHE_IA_INT_PRO_DROM0 — PRO CPU invalid access to DROM0 when cache is disabled
  [5] CACHE_IA_INT_APP_OPPOSITE — APP CPU invalid access to APP CPU cache when cache disabled
  [4] CACHE_IA_INT_APP_DRAM1 — APP CPU invalid access to DRAM1 when cache is disabled
  [3] CACHE_IA_INT_APP_IROM0 — APP CPU invalid access to IROM0 when cache is disabled
  [2] CACHE_IA_INT_APP_IRAM1 — APP CPU invalid access to IRAM1 when cache is disabled
  [1] CACHE_IA_INT_APP_IRAM0 — APP CPU invalid access to IRAM0 when cache is disabled
  [27:0] CACHE_IA_INT_EN — Interrupt enable bits for various invalid cache access reasons
  [0] CACHE_IA_INT_APP_DROM0 — APP CPU invalid access to DROM0 when cache is disabled
0x5A4 SECURE_BOOT_CTRL
  [0] SW_BOOTLOADER_SEL
0x5A8 SPI_DMA_CHAN_SEL
  [5:4] SPI3_DMA_CHAN_SEL, [3:2] SPI2_DMA_CHAN_SEL, [1:0] SPI1_DMA_CHAN_SEL
0x5AC PRO_VECBASE_CTRL
  [1:0] PRO_OUT_VECBASE_SEL
0x5B0 PRO_VECBASE_SET
  [21:0] PRO_OUT_VECBASE
0x5B4 APP_VECBASE_CTRL
  [1:0] APP_OUT_VECBASE_SEL
0x5B8 APP_VECBASE_SET
  [21:0] APP_OUT_VECBASE
0xFFC DATE reset 0x1605190
  [27:0] DATE

## Notices in the file
Copyright 2025 Espressif Systems (Shanghai) PTE LTD
Licensed under the Apache License, Version 2.0 (the "License");
you may not use this file except in compliance with the License.
You may obtain a copy of the License at
http://www.apache.org/licenses/LICENSE-2.0
Unless required by applicable law or agreed to in writing, software
distributed under the License is distributed on an "AS IS" BASIS,
WITHOUT WARRANTIES OR CONDITIONS OF ANY KIND, either express or implied.
See the License for the specific language governing permissions and
limitations under the License.
